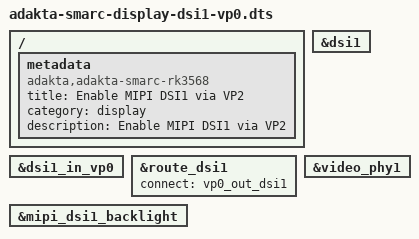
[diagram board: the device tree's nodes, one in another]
/dts-v1/;
/plugin/;

/ {
	metadata {
		title = "Enable MIPI DSI1 via VP2";
		compatible = "adakta,adakta-smarc-rk3568";
		category = "display";
		description = "Enable MIPI DSI1 via VP2";
	};

	fragment@0 {
		target = <&dsi1>;

		__overlay__ {
			status = "okay";
		};
	};

	fragment@1 {
		target = <&dsi1_in_vp0>;

		__overlay__ {
			status = "okay";
		};
	};

	fragment@2 {
		target = <&route_dsi1>;

		__overlay__ {
			status = "okay";
			connect = <&vp0_out_dsi1>;
		};
	};

	fragment@3 {
		target = <&mipi_dsi1_backlight>;

		__overlay__ {
			status = "okay";
		};
	};

	fragment@4 {
		target = <&video_phy1>;

		__overlay__ {
			status = "okay";
		};
	};
};
